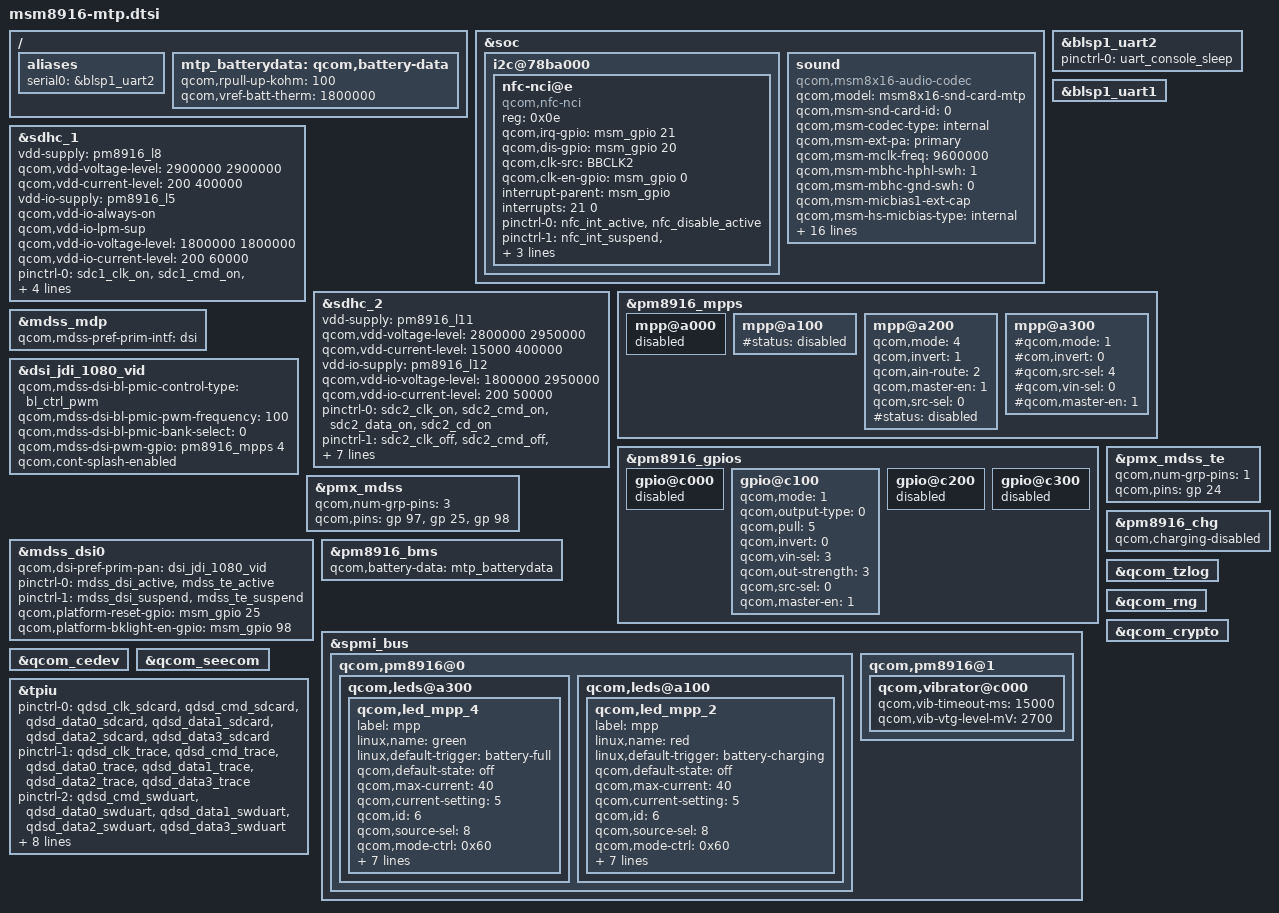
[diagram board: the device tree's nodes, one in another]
/* Copyright (c) 2014, The Linux Foundation. All rights reserved.
 *
 * This program is free software; you can redistribute it and/or modify
 * it under the terms of the GNU General Public License version 2 and
 * only version 2 as published by the Free Software Foundation.
 *
 * This program is distributed in the hope that it will be useful,
 * but WITHOUT ANY WARRANTY; without even the implied warranty of
 * MERCHANTABILITY or FITNESS FOR A PARTICULAR PURPOSE.  See the
 * GNU General Public License for more details.
 */

#include "msm8916.dtsi"
#include "msm8916-pinctrl.dtsi"
/*
  * deleted  qcom default camera sensor dtsi file  
  *
  * by ZTE_YCM_20140709 yi.changming 000001
  */
// --->
//#include "msm8916-camera-sensor-mtp.dtsi"
// <---



/ {
	aliases {
		serial0 = &blsp1_uart2;
	};
};

&soc {
	i2c@78ba000 { /* BLSP1 QUP6 */
		nfc-nci@e {
			compatible = "qcom,nfc-nci";
			reg = <0x0e>;
			qcom,irq-gpio = <&msm_gpio 21 0x00>;
			qcom,dis-gpio = <&msm_gpio 20 0x00>;
			qcom,clk-src = "BBCLK2";
			qcom,clk-en-gpio = <&msm_gpio 0 0x00>;
			interrupt-parent = <&msm_gpio>;
			interrupts = <21 0>;
			interrupt-names = "nfc_irq";
			pinctrl-names = "nfc_active","nfc_suspend";
			pinctrl-0 = <&nfc_int_active &nfc_disable_active>;
			pinctrl-1 = <&nfc_int_suspend &nfc_disable_suspend>;
			qcom,clk-gpio = <&pm8916_gpios 2 0>;
			clocks = <&clock_rpm clk_bb_clk2_pin>;
			clock-names = "ref_clk";
		};
	};

	sound {
		compatible = "qcom,msm8x16-audio-codec";
		qcom,model = "msm8x16-snd-card-mtp";
		qcom,msm-snd-card-id = <0>;
		qcom,msm-codec-type = "internal";
		qcom,msm-ext-pa = "primary";
		qcom,msm-mclk-freq = <9600000>;
		qcom,msm-mbhc-hphl-swh = <1>;
		qcom,msm-mbhc-gnd-swh = <0>;
		qcom,msm-micbias1-ext-cap;
		qcom,msm-hs-micbias-type = "internal";
		qcom,audio-routing =
			"RX_BIAS", "MCLK",
			"SPK_RX_BIAS", "MCLK",
			"INT_LDO_H", "MCLK",
			"MIC BIAS External", "Handset Mic",
			"MIC BIAS Internal2", "Headset Mic",
			"MIC BIAS External", "Secondary Mic",
			"AMIC1", "MIC BIAS External",
			"AMIC2", "MIC BIAS Internal2",
			"AMIC3", "MIC BIAS External";
		pinctrl-names = "cdc_lines_act",
				"cdc_lines_sus",
				"cdc_lines_sec_ext_act",
				"cdc_lines_sec_ext_sus",
				"cross_conn_det_act",
				"cross_conn_det_sus";
		pinctrl-0 = <&cdc_pdm_lines_act>;
		pinctrl-1 = <&cdc_pdm_lines_sus>;
		pinctrl-2 = <&cdc_pdm_lines_act &cdc_ext_pa_act
						&cdc_ext_pa_ws_act>;
		pinctrl-3 = <&cdc_pdm_lines_sus &cdc_ext_pa_sus
						&cdc_ext_pa_ws_sus>;
		pinctrl-4 = <&cross_conn_det_act>;
		pinctrl-5 = <&cross_conn_det_sus>;
		qcom,cdc-us-euro-gpios = <&msm_gpio 120 0>;
	};
};

&blsp1_uart2 {
	status = "ok";
	pinctrl-names = "default";
	pinctrl-0 = <&uart_console_sleep>;
};



&blsp1_uart1 {
	status = "ok";
};

&sdhc_1 {
	vdd-supply = <&pm8916_l8>;
	qcom,vdd-voltage-level = <2900000 2900000>;
	qcom,vdd-current-level = <200 400000>;

	vdd-io-supply = <&pm8916_l5>;
	qcom,vdd-io-always-on;
	qcom,vdd-io-lpm-sup;
	qcom,vdd-io-voltage-level = <1800000 1800000>;
	qcom,vdd-io-current-level = <200 60000>;

	pinctrl-names = "active", "sleep";
	pinctrl-0 = <&sdc1_clk_on &sdc1_cmd_on &sdc1_data_on>;
	pinctrl-1 = <&sdc1_clk_off &sdc1_cmd_off &sdc1_data_off>;

	qcom,nonremovable;

	status = "ok";
};

&sdhc_2 {
	vdd-supply = <&pm8916_l11>;
	qcom,vdd-voltage-level = <2800000 2950000>;
	qcom,vdd-current-level = <15000 400000>;

	vdd-io-supply = <&pm8916_l12>;
	qcom,vdd-io-voltage-level = <1800000 2950000>;
	qcom,vdd-io-current-level = <200 50000>;

	pinctrl-names = "active", "sleep";
	pinctrl-0 = <&sdc2_clk_on &sdc2_cmd_on &sdc2_data_on &sdc2_cd_on>;
	pinctrl-1 = <&sdc2_clk_off &sdc2_cmd_off &sdc2_data_off &sdc2_cd_off>;

	#address-cells = <0>;
	interrupt-parent = <&sdhc_2>;
	interrupts = <0 1 2>;
	#interrupt-cells = <1>;
	interrupt-map-mask = <0xffffffff>;
	interrupt-map = <0 &intc 0 125 0
			1 &intc 0 221 0
			2 &msm_gpio 38 0>;
	interrupt-names = "hc_irq", "pwr_irq", "status_irq";
	cd-gpios = <&msm_gpio 38 0x1>;

	status = "ok";
};

&pm8916_mpps {
	mpp@a000 { /* MPP 1 */
		/* VDD_PX */
		status = "disabled";
	};

	mpp@a100 { /* MPP 2 */
		/* HR LED */
		#status = "disabled";						/*zte enable mpp2*/
	};

	mpp@a200 { /* MPP 3 */
		/* PA_THERM config */		/*zte jiangfeng*/
		qcom,mode = <4>; 		/* AIN input */
		qcom,invert = <1>; 	/* Enable MPP */
		qcom,ain-route = <2>; 	/* AMUX 7 */
		qcom,master-en = <1>;
		qcom,src-sel = <0>; 	/* Function constant */
		#status = "disabled";
	};

	mpp@a300 { /* MPP 4 */
		/* Backlight PWM */
		#qcom,mode = <1>;		/* Digital output */
		#com,invert = <0>;		/* Disable invert */
		#qcom,src-sel = <4>;		/* DTEST1 */
		#qcom,vin-sel = <0>;		/* VPH_PWR */
		#qcom,master-en = <1>;		/* Enable MPP */
	};
};

&pm8916_gpios {
	gpio@c000 { /* GPIO 1 */
		/* Battery UICC Alarm */
		status = "disabled";
	};

	gpio@c100 { /* GPIO 2 */
/*  changed  by zte jiangzhineng, GPIO 2 used as battery switch */
         qcom,mode = <1>;
         qcom,output-type = <0>;
         qcom,pull = <5>;
         qcom,invert = <0>;
         qcom,vin-sel = <3>;
         qcom,out-strength = <3>;
         qcom,src-sel = <0>;
		qcom,master-en = <1>;
	};

	gpio@c200 { /* GPIO 3 */
		/* External regulator control for WTR */
		status = "disabled";
	};

	gpio@c300 { /* GPIO 4 */
		/* External regulator control for APC */
		status = "disabled";
	};
};

#include "dsi-panel-jdi-1080p-video.dtsi"

&mdss_mdp {
	qcom,mdss-pref-prim-intf = "dsi";
};

&dsi_jdi_1080_vid {
	qcom,mdss-dsi-bl-pmic-control-type = "bl_ctrl_pwm";
	qcom,mdss-dsi-bl-pmic-pwm-frequency = <100>;
	qcom,mdss-dsi-bl-pmic-bank-select = <0>;
	qcom,mdss-dsi-pwm-gpio = <&pm8916_mpps 4 0>;

};

&pmx_mdss {
	qcom,num-grp-pins = <3>;
	qcom,pins = <&gp 97>, <&gp 25>, <&gp 98>;
};

&pmx_mdss_te {
	qcom,num-grp-pins = <1>;
	qcom,pins = <&gp 24>;
};

&mdss_dsi0 {
	qcom,dsi-pref-prim-pan = <&dsi_jdi_1080_vid>;
	pinctrl-names = "mdss_default", "mdss_sleep";
	pinctrl-0 = <&mdss_dsi_active &mdss_te_active>;
	pinctrl-1 = <&mdss_dsi_suspend &mdss_te_suspend>;

	//qcom,platform-enable-gpio = <&msm_gpio 97 0>;
	qcom,platform-reset-gpio = <&msm_gpio 25 0>;
	qcom,platform-bklight-en-gpio = <&msm_gpio 98 0>;
};

&dsi_jdi_1080_vid {
       qcom,cont-splash-enabled;
};

&pm8916_chg {
	status = "ok";
	qcom,charging-disabled;
};

/ {
	mtp_batterydata: qcom,battery-data {
		qcom,rpull-up-kohm = <100>;
		qcom,vref-batt-therm = <1800000>;

		#include "batterydata-palladium.dtsi"
	};
};

&pm8916_bms {
	status = "ok";
	qcom,battery-data = <&mtp_batterydata>;
};

/*zte add*/
&spmi_bus {
	qcom,pm8916@0 {
		qcom,leds@a300 {
			status = "okay";
			qcom,led_mpp_4 {	/* green led */
				label = "mpp";
				linux,name = "green";		/* orgin is wled-backlight */
				linux,default-trigger = "battery-full";	/* org="bkl-trigger"; */
				qcom,default-state = "off";
				qcom,max-current = <40>;
				qcom,current-setting = <5>;	/* zte add */
				qcom,id = <6>;				/* in leds-qpnp.c enum QPNP_ID_LED_MPP(6) */
				qcom,source-sel = <8>;		/* select power source, default 1 (enabled)(org=8) */
				qcom,mode-ctrl = <0x60>;	/* operation mode, default 0x60 = Mode Sink (org=0x10)*/
				qcom,pwm-channel = <0>;
				qcom,pwm-us = <1000>;
				qcom,vin-ctrl = <0x00>;		/* select input source, 0 to 3 */
				qcom,duty-pcts = <50>;
				qcom,mode = "pwm";
				qcom,use-blink;
				#qcom,min-brightness = <19>;
			};
		};
		qcom,leds@a100 {
			status = "okay";
			qcom,led_mpp_2 {	/* red led */
				label = "mpp";
				linux,name = "red";
				linux,default-trigger = "battery-charging";
				qcom,default-state = "off";
				qcom,max-current = <40>;
				qcom,current-setting = <5>;
				qcom,id = <6>;
				qcom,source-sel = <8>;
				qcom,mode-ctrl = <0x60>;
				qcom,pwm-channel = <0>;
				qcom,pwm-us = <1000>;
				qcom,vin-ctrl = <0x00>;
				qcom,duty-pcts = <50>;
				qcom,mode = "pwm";
				qcom,use-blink;
				#qcom,min-brightness = <19>;
			};
		};
	};
};

&qcom_tzlog {
	status = "okay";
};

&qcom_rng {
	status = "okay";
};

&qcom_crypto {
	status = "okay";
};

&qcom_cedev {
	status = "okay";
};

&qcom_seecom {
	status = "okay";
};

/* CoreSight */
&tpiu {
      pinctrl-names = "sdcard", "trace", "swduart",
		      "swdtrc", "jtag", "spmi";
       /* NIDnT */
      pinctrl-0 = <&qdsd_clk_sdcard &qdsd_cmd_sdcard
                  &qdsd_data0_sdcard &qdsd_data1_sdcard
                  &qdsd_data2_sdcard &qdsd_data3_sdcard>;
      pinctrl-1 = <&qdsd_clk_trace &qdsd_cmd_trace
                  &qdsd_data0_trace &qdsd_data1_trace
                  &qdsd_data2_trace &qdsd_data3_trace>;
      pinctrl-2 = <&qdsd_cmd_swduart &qdsd_data0_swduart
                  &qdsd_data1_swduart &qdsd_data2_swduart
                  &qdsd_data3_swduart>;
      pinctrl-3 = <&qdsd_clk_swdtrc &qdsd_cmd_swdtrc
                  &qdsd_data0_swdtrc &qdsd_data1_swdtrc
                  &qdsd_data2_swdtrc &qdsd_data3_swdtrc>;
      pinctrl-4 = <&qdsd_cmd_jtag &qdsd_data0_jtag
                  &qdsd_data1_jtag &qdsd_data2_jtag
                  &qdsd_data3_jtag>;
      pinctrl-5 = <&qdsd_clk_spmi &qdsd_cmd_spmi
                  &qdsd_data0_spmi &qdsd_data3_spmi>;
};

&spmi_bus {
	qcom,pm8916@1 {
		qcom,vibrator@c000 {
			status = "okay";
			qcom,vib-timeout-ms = <15000>;
			qcom,vib-vtg-level-mV = <2700>;/*zte change 3100 to 2700 in 8916,hardware require*/
		};
	};
};
